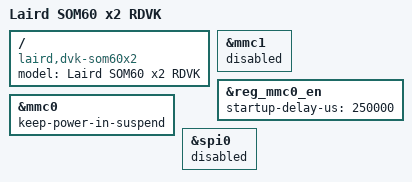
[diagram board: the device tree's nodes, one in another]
// SPDX-License-Identifier: GPL-2.0
/*
 * at91-dvk_som60.dts - Device Tree file for the DVK SOM60 board
 *
 *  Copyright (C) 2018 Laird Connectivity,
 *		  2018 Ben Whitten <ben.whitten@lairdconnect.com>
 *		  2018 Boris Krasnovskiy <boris.krasnovskiy@lairdconnect.com>
 *
 * Licensed under GPLv2 or later.
 */

/dts-v1/;

/* SOM60 module definition */
#include "at91-som60.dtsi"

/* DVK board definition */
#include "at91-dvk_su60_somc.dtsi"

/* Display & touchscreen definition */
#include "at91-dvk_su60_somc_lcm.dtsi"

/* On-board radio disabled */
&mmc1 {
    status = "disabled";
};

/*
 * LWB/LWB5/LWB5+ requires minimum 150ms after power-up until first access
 * Testing shows this isn't always sufficient
 */
&reg_mmc0_en {
    startup-delay-us = <250000>;
};

&mmc0 {
	keep-power-in-suspend;
};

&spi0 {
    status = "disabled";
};

/ {
    model = "Laird SOM60 x2 RDVK";
    compatible = "laird,dvk-som60x2", "laird,lwb-som60x2", "laird,som60x2", "atmel,sama5d36", "atmel,sama5d3", "atmel,sama5";
};
